AUTOSAR XML (schema 00046)
standard types defined: uint8, uint8_DataConstr
package /ComponentTypes/CanBusOffSWC
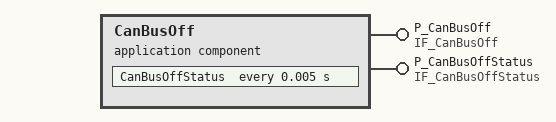
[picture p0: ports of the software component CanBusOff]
  application sw component type CanBusOff
    provide port P_CanBusOff: provided-interface=IF_CanBusOff
      provided-com-specs:
        operation=Can_BusOffIndicated, queue-length=1
        operation=CanBusOff_Begin, queue-length=1
        operation=CanBusOff_End, queue-length=1
    provide port P_CanBusOffStatus: nonqueued-sender-com-spec{data-element=CanBusOffSatus, init-value=0}, provided-interface=IF_CanBusOffStatus
    behavior CanBusOff_InternalBehavior
      timing event CanBusOffStatus_TE: start-on-event=CanBusOffStatus, period=0.005
      operation invoked event OIT_P_CanBusOff_Can_BusOffIndicated_P_CanBusOff_Can_BusOffIndicated: start-on-event=P_CanBusOff_Can_BusOffIndicated, operation=P_CanBusOff.Can_BusOffIndicated
      operation invoked event OIT_P_CanBusOff_CanBusOff_Begin_P_CanBusOff_CanBusOff_Begin: start-on-event=P_CanBusOff_CanBusOff_Begin, operation=P_CanBusOff.CanBusOff_Begin
      operation invoked event OIT_P_CanBusOff_CanBusOff_End_P_CanBusOff_CanBusOff_End: start-on-event=P_CanBusOff_CanBusOff_End, operation=P_CanBusOff.CanBusOff_End
      4 x runnable:
        CanBusOffStatus
        P_CanBusOff_Can_BusOffIndicated
        P_CanBusOff_CanBusOff_Begin
        P_CanBusOff_CanBusOff_End
  swc implementation CanBusOff_Implementation: behavior=CanBusOff_InternalBehavior
    code-descriptors:
      code Default: artifact-descriptors=autosar-engineering-object={short-label=Default, category=SWSRC}
package /ComponentTypes/CanBusOffSWC/PortInterfaces
  client server interface IF_CanBusOff: is-service=true
    operation Can_BusOffIndicated
      arg networkHandle: type=uint8, direction=OUT, server-argument-impl-policy=USE-ARGUMENT-TYPE
    operation CanBusOff_Begin
      arg networkHandle: type=uint8, direction=INOUT, server-argument-impl-policy=USE-ARGUMENT-TYPE
    operation CanBusOff_End
      arg networkHandle: type=uint8, direction=OUT, server-argument-impl-policy=USE-ARGUMENT-TYPE
  sender receiver interface IF_CanBusOffStatus: invalidation-policy{data-element=CanBusOffSatus, handle-invalid=DONT-INVALIDATE}
    data CanBusOffSatus: type=uint8
